# GD32F350 register map
File version: 1.0
CPU: CM4 r0p1, little endian, no MPU, FPU, 4 interrupt priority bits
Registers are 32-bit, read-write, reset 0x0 unless marked. A register's access mark holds for its fields unless they carry their own. Offsets are from the block's base; [hi:lo] are bit positions; {n}, {i} and the like mark numbered series.

## I2C0 — Inter integrated circuit
Base 0x40005400
Same registers: I2C1 0x40005800
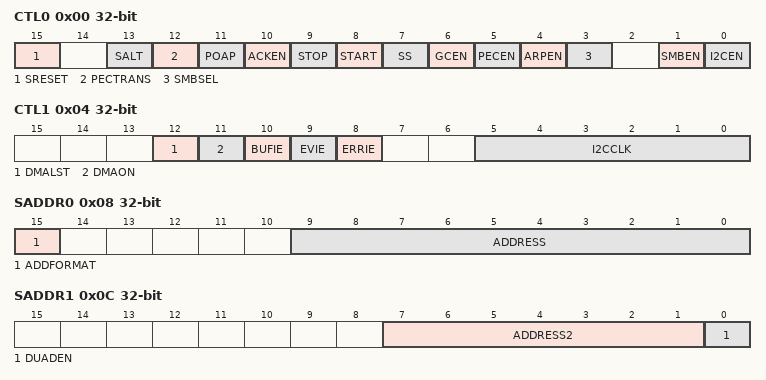
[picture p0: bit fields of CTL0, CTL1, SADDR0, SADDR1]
0x00 CTL0 — Control register 0
  [15] SRESET — Software reset
  [13] SALT — SMBus alert
  [12] PECTRANS — Packet error checking
  [11] POAP — Acknowledge/PEC Position (for data reception)
  [10] ACKEN — Acknowledge enable
  [9] STOP — Stop condition
  [8] START — Start generation
  [7] SS — Clock stretching disable (Slave mode)
  [6] GCEN — General call enable
  [5] PECEN — PEC enable
  [4] ARPEN — ARP enable
  [3] SMBSEL — SMBus type
  [1] SMBEN — SMBus mode
  [0] I2CEN — Peripheral enable
0x04 CTL1 — Control register 1
  [12] DMALST — Flag indicating DMA last transfer
  [11] DMAON — DMA mode switch
  [10] BUFIE — Buffer interrupt enable
  [9] EVIE — Event interrupt enable
  [8] ERRIE — Error interrupt enable
  [5:0] I2CCLK — Peripheral clock frequency
0x08 SADDR0 — Own address register 0
  [15] ADDFORMAT — Addressing mode (slave mode)
  [9:0] ADDRESS — Interface address
0x0C SADDR1 — Own address register 1
  [7:1] ADDRESS2 — Interface address
  [0] DUADEN — Dual addressing mode enable
0x10 DATA
  [7:0] TRB — Transmission or reception data buffer
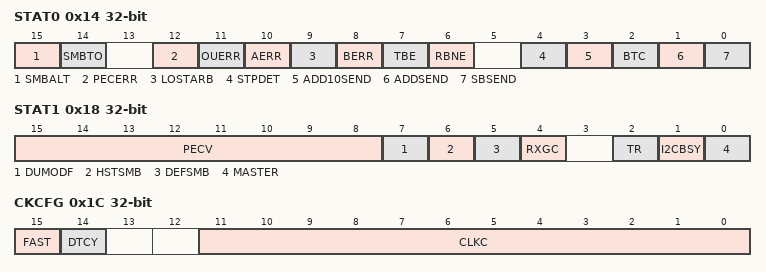
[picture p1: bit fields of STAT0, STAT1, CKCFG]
0x14 STAT0 access per field — Transfer status register 0
  [15] SMBALT rw — SMBus alert
  [14] SMBTO rw — Timeout signal in SMBus mode
  [12] PECERR rw — PEC error when receiving data
  [11] OUERR rw — Overrun/Underrun occurs in slave mode
  [10] AERR rw — Acknowledge error
  [9] LOSTARB rw — Arbitration lost (master mode)
  [8] BERR rw — Bus error
  [7] TBE ro — I2C_DATA is Empty during transmitting
  [6] RBNE ro — I2C_DATA is not Empty during receiving
  [4] STPDET ro — Stop detection (slave mode)
  [3] ADD10SEND ro — Header of 10-bit address is sent in master mode
  [2] BTC ro — Byte transmission completed
  [1] ADDSEND ro — Address sent (master mode)/matched (slave mode)
  [0] SBSEND ro — Start bit (Master mode)
0x18 STAT1 ro — Transfer status register 1
  [15:8] PECV — Packet error checking register
  [7] DUMODF — Dual flag (Slave mode)
  [6] HSTSMB — SMBus host header (Slave mode)
  [5] DEFSMB — SMBus device default address (Slave mode)
  [4] RXGC — General call address (Slave mode)
  [2] TR — Transmitter/receiver
  [1] I2CBSY — Bus busy
  [0] MASTER — Master/slave
0x1C CKCFG — Clock configure register
  [15] FAST — I2C master mode selection
  [14] DTCY — Fast mode duty cycle
  [11:0] CLKC — Clock control register in Fast/Standard mode (Master mode)
0x20 RT reset 0x2 — Rise time register
  [5:0] RISETIME — Maximum rise time in master mode
0x90 FMPCFG — Fast-mode-plus configure register
  [0] FMPEN — Fast-mode-plus enable

## NVIC — Nested Vectored Interrupt Controller
Base 0xE000E100
0x00 ISER — Interrupt Set Enable Register
  [31:0] SETENA
0x80 ICER — Interrupt Clear Enable Register
  [31:0] CLRENA
0x100 ISPR — Interrupt Set-Pending Register
  [31:0] SETPEND
0x180 ICPR — Interrupt Clear-Pending Register
  [31:0] CLRPEND
0x200 IABR — Interrupt Active bit Register
{0x300+i} IPR{i} 8-bit (i=0..73) — Interrupt Priority Register {i}
  [7:0] PRI_{i:02}
0xE00 STIR wo — Software Trigger Interrupt Register

## PMU — Power management unit
Base 0x40007000
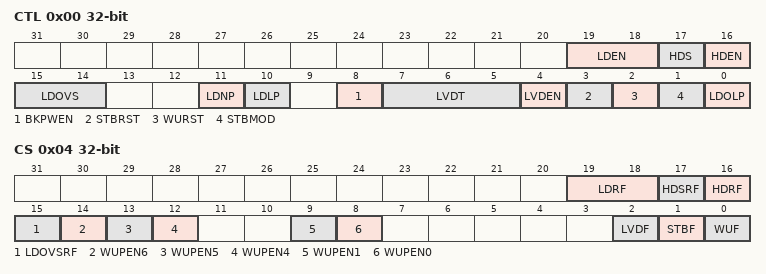
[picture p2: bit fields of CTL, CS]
0x00 CTL — power control register
  [19:18] LDEN — Low-driver mode enable in Deep-sleep mode
  [17] HDS — High-driver mode switch
  [16] HDEN — High-driver mode enable
  [15:14] LDOVS — LDO output voltage select
  [11] LDNP — Low-driver mode when use normal power LDO
  [10] LDLP — Low-driver mode when use low power LDO
  [8] BKPWEN — Backup Domain Write Enable
  [7:5] LVDT — Low Voltage Detector Threshold
  [4] LVDEN — Low Voltage Detector Enable
  [3] STBRST — Standby Flag Reset
  [2] WURST — Wakeup Flag Reset
  [1] STBMOD — Standby Mode
  [0] LDOLP — LDO Low Power Mode
0x04 CS access per field — power control/status register
  [19:18] LDRF rw — Low-driver mode ready flag
  [17] HDSRF rw — High-driver switch ready flag
  [16] HDRF rw — High-driver ready flag
  [15] LDOVSRF rw — LDO voltage select ready flag
  [14] WUPEN6 rw — WKUP pin6 Enable
  [13] WUPEN5 rw — WKUP pin5 Enable
  [12] WUPEN4 rw — WKUP pin4 Enable
  [9] WUPEN1 rw — WKUP pin1 Enable
  [8] WUPEN0 rw — WKUP pin0 Enable
  [2] LVDF ro — Low Voltage Detector Status Flag
  [1] STBF ro — Standby flag
  [0] WUF ro — Wakeup flag
